# STM32F732 register map
File version: 1.4
CPU: CM7 r0p1, little endian, MPU, FPU, 4 interrupt priority bits
Registers are 32-bit, read-write, reset 0x0 unless marked. A register's access mark holds for its fields unless they carry their own. Offsets are from the block's base; [hi:lo] are bit positions; {n}, {i} and the like mark numbered series; 'fields as' and 'values as' point back to an identical list.

## FLASH
Base 0x40023C00
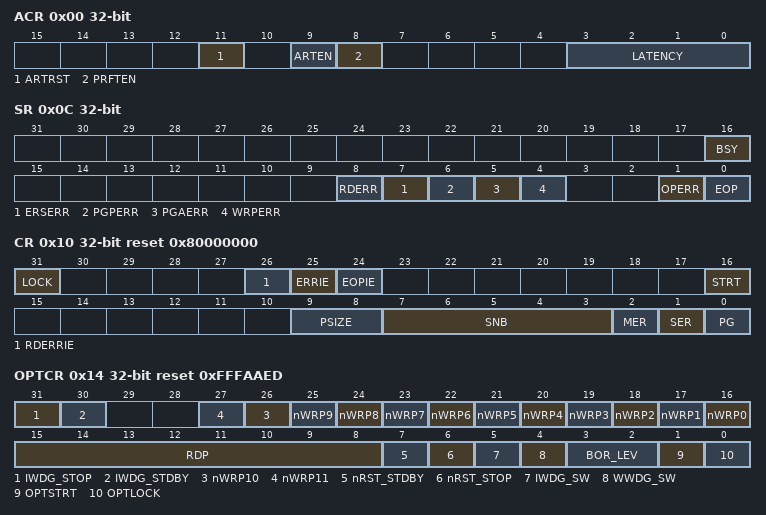
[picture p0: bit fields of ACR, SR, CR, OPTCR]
0x00 ACR — Flash access control register
  [11] ARTRST — ART Accelerator reset
    0=NoReset (Accelerator is not reset); 1=Reset (Accelerator is reset)
  [9] ARTEN — ART Accelerator Enable
    0=Disabled (ART Accelerator is disabled); 1=Enabled (ART Accelerator is enabled)
  [8] PRFTEN — Prefetch enable
    0=Disabled (Prefetch is disabled); 1=Enabled (Prefetch is enabled)
  [3:0] LATENCY
    {v}=WS{v} ({v} wait states) (v=0..15)
0x04 KEYR wo — Flash key register
  [31:0] KEY — FPEC key
0x08 OPTKEYR wo — Flash option key register
  [31:0] OPTKEYR — Option byte key
0x0C SR access not given — Status register
  [16] BSY ro — Busy
    0=NotBusy (No Flash memory operation ongoing); 1=Busy (Flash memory operation ongoing)
  [8] RDERR write-1-clears — Read Protection Error (PCROP)
    on read: 0=Inactive (No error); 1=Active (A read access through the D-bus is performed to an address belonging to a proprietary readout protected Flash sector) | on write: 1=Clear error flag
  [7] ERSERR rw write-1-clears — Erase Sequence Error
    on read: 0=Inactive (No error); 1=Active (A write access to the Flash memory is performed by the code while the control register has not been correctly configured) | on write: 1=Clear error flag
  [6] PGPERR rw write-1-clears — Programming parallelism error
    on read: 0=Inactive (No error); 1=Active (The size of the access during the program sequence doesn't correspond to the parallelism configuration PSIZE) | on write: 1=Clear error flag
  [5] PGAERR rw write-1-clears — Programming alignment error
    on read: 0=Inactive (No error); 1=Active (The data to program cannot be contained in the same 128-bit Flash memory row) | on write: 1=Clear error flag
  [4] WRPERR rw write-1-clears — Write protection error
    on read: 0=Inactive (No error); 1=Active (The address to be erased/programmed belongs to a write-protected part of the Flash memory) | on write: 1=Clear error flag
  [1] OPERR rw write-1-clears — Operation error
    on read: 0=Inactive (No error); 1=Active (A Flash operation request is detected and cannot be run because of parallelism) | on write: 1=Clear error flag
  [0] EOP rw write-1-clears — End of operation
    on read: 0=Inactive (No error); 1=Active (One or more Flash operations has/have completed successfully) | on write: 1=Clear error flag
0x10 CR reset 0x80000000 — Control register
  [31] LOCK
    0=Unlocked (FLASH_CR register is unlocked); 1=Locked (FLASH_CR register is locked)
  [26] RDERRIE — PCROP error interrupt enable
    0=Disabled (PCROP error interrupt generation disabled); 1=Enabled (PCROP error interrupt generation enabled)
  [25] ERRIE — Error interrupt enable
    0=Disabled (Error interrupt generation disabled); 1=Enabled (Error interrupt generation enabled)
  [24] EOPIE — End of operation interrupt enable
    0=Disabled (End of operation interrupt disabled); 1=Enabled (End of operation interrupt enabled)
  [16] STRT — Start
    1=Start (Trigger an erase operation)
  [9:8] PSIZE — Program size
    0=Program x8; 1=Program x16; 2=Program x32; 3=Program x64
  [7:3] SNB range 0..11 — Sector number
  [2] MER — Mass Erase of sectors 0 to 11
    1=MassErase (Erase activated for all user sectors)
  [1] SER — Sector Erase
    1=SectorErase (Erase activated for selected sector)
  [0] PG — Programming
    1=Program (Flash programming activated)
0x14 OPTCR reset 0xFFFAAED — Flash option control register
  [31] IWDG_STOP — Independent watchdog counter freeze in Stop mode
    0=Inactive (IWDG counter frozen in Stop mode); 1=Active (IWDG counter active in Stop mode)
  [30] IWDG_STDBY — Independent watchdog counter freeze in standby mode
    0=Inactive (IWDG counter frozen in Standby mode); 1=Active (IWDG counter active in Standby mode)
  [n+16] nWRP{n} (n=0..11) — Not write protect
    0=Active (Write protection active on sector %s); 1=Inactive (Write protection inactive on sector %s)
  [15:8] RDP — Read protect
    170=Level0 (Read protection not active); 204=Level2 (Chip read protection active); other=Level1 (Read protection of memories active)
  [7] nRST_STDBY — nRST_STDBY User option bytes
    0=Reset generated when entering Standby mode; 1=No reset generated
  [6] nRST_STOP — nRST_STOP User option bytes
    0=Reset generated when entering Stop mode; 1=No reset generated
  [5] IWDG_SW — WDG_SW User option bytes
    0=Hardware independant watchdog; 1=Software independant watchdog
  [4] WWDG_SW — User option bytes
    0=Hardware window watchdog; 1=Software window watchdog
  [3:2] BOR_LEV — BOR reset Level
    0=BOR_Off (Reset threshold level for POR/PDR (around 1.7V)); 1=BOR_Level1 (Reset threshold level for VBOR1 (around 2.2 V)); 2=BOR_Level2 (Reset threshold level for VBOR2 (around 2.5 V)); 3=BOR_Level3 (Reset threshold level for VBOR3 (around 2.8 V))
  [1] OPTSTRT — Option start
    on read: 0=Complete (Cleared when BSY bit is cleared in SR); 1=Requested (Options modification requested) | on write: 1=Set (This bit triggers an options operation when set)
  [0] OPTLOCK — Option lock
    on read: 0=Unlocked (The write and erase operations in the Option bytes area are disabled); 1=Locked (The write and erase operations in the Option bytes area are enabled) | on write: 1=Set (Lock the FLASH_OPTCR register)
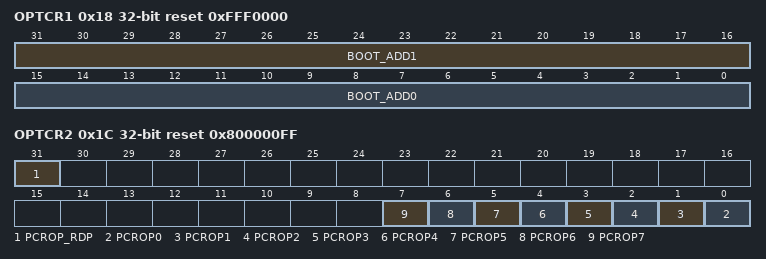
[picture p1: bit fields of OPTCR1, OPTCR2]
0x18 OPTCR1 reset 0xFFF0000 — Flash option control register 1
  [31:16] BOOT_ADD1 — Boot base address when Boot pin =1
    0=ItcmRam (Boot from ITCM RAM (0x0000 0000)); 64=SystemMemoryBootloader (Boot from System memory bootloader (0x0010 0000)); 128=FlashItcmInterface (Boot from Flash on ITCM interface (0x0020 0000)); 0x2000=FlashAximInterface (Boot from Flash on AXIM interface (0x0800 0000)); 0x8000=DtcmRam (Boot from DTCM RAM (0x2000 0000)); 0x8004=Sram1 (Boot from SRAM1 (0x2001 0000)); 0x8013=Sram2 (Boot from SRAM2 (0x2003 C000)); other=BootAddress (Boot from specified address (granularity of 16KB))
  [15:0] BOOT_ADD0 — Boot base address when Boot pin =0
    values as BOOT_ADD1
0x1C OPTCR2 reset 0x800000FF — Flash option control register
  [31] PCROP_RDP — PCROP zone preserved when RDP level decreased
    0=Inactive (PCROP protection inactive on sector %s); 1=Active (PCROP protection active on sector %s)
  [n] PCROP{n} (n=0..7) — PCROP option byte
    values as PCROP_RDP
